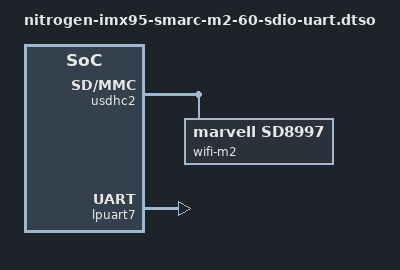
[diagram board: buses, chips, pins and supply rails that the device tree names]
// SPDX-License-Identifier: (GPL-2.0+ OR MIT)
/*
 * SDIO 60 SDIO-UART module
 *
 * Copyright (C) 2024 Ezurio LLC
 */

/dts-v1/;
/plugin/;

#include <dt-bindings/gpio/gpio.h>

// M.2 SDIO is disabled by default on SMARC carrier board
// requires switching 0 Ohm resistors to enable	

&reg_usdhc2_vmmc {
	vin-supply = <&reg_slow_clock_carrier>;

	startup-delay-us = <1000>;
	off-on-delay-us = <100000>;
};

&usdhc2 {
	wifi-m2 {
		compatible = "marvell,sd8997";
		fwtype = "sdio-uart";
	};
};

&lpuart7 {
	status = "okay";
};
